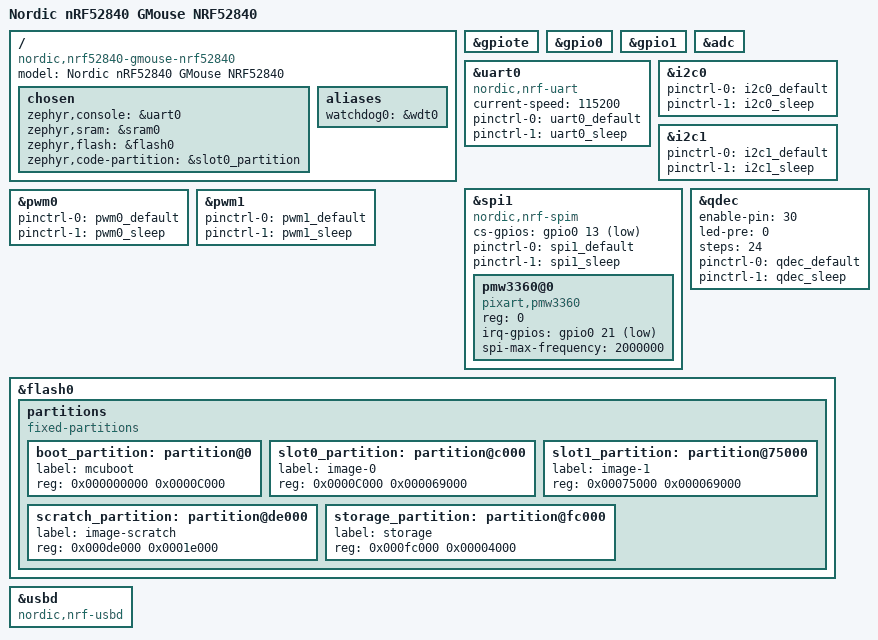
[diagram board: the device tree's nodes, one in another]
/*
 * Copyright (c) 2018-2022 Nordic Semiconductor ASA
 *
 * SPDX-License-Identifier: LicenseRef-Nordic-5-Clause
 */

/dts-v1/;
#include <nordic/nrf52840_qiaa.dtsi>
#include "nrf52840gmouse_nrf52840-pinctrl.dtsi"

/ {
	model = "Nordic nRF52840 GMouse NRF52840";
	compatible = "nordic,nrf52840-gmouse-nrf52840";

	chosen {
		zephyr,console = &uart0;
		zephyr,sram = &sram0;
		zephyr,flash = &flash0;
		zephyr,code-partition = &slot0_partition;
	};

	/* These aliases are provided for compatibility with samples */
	aliases {
		watchdog0 = &wdt0;
	};
};

&gpiote {
	status = "okay";
};

&gpio0 {
	status = "okay";
};

&gpio1 {
	status = "okay";
};

&adc {
	status = "okay";
};

&uart0 {
	status = "okay";
	compatible = "nordic,nrf-uart";
	current-speed = <115200>;
	pinctrl-0 = <&uart0_default>;
	pinctrl-1 = <&uart0_sleep>;
	pinctrl-names = "default", "sleep";
};

&i2c0 {
	status = "okay";
	pinctrl-0 = <&i2c0_default>;
	pinctrl-1 = <&i2c0_sleep>;
	pinctrl-names = "default", "sleep";
};

&i2c1 {
	status = "okay";
	pinctrl-0 = <&i2c1_default>;
	pinctrl-1 = <&i2c1_sleep>;
	pinctrl-names = "default", "sleep";
};

&spi1 {
	compatible = "nordic,nrf-spim";
	status = "okay";
	cs-gpios = <&gpio0 13 GPIO_ACTIVE_LOW>;

	pinctrl-0 = <&spi1_default>;
	pinctrl-1 = <&spi1_sleep>;
	pinctrl-names = "default", "sleep";
	pmw3360@0 {
		compatible = "pixart,pmw3360";
		reg = <0>;
		irq-gpios = <&gpio0 21 (GPIO_ACTIVE_LOW | GPIO_PULL_UP)>;
		spi-max-frequency = <2000000>;
	};
};

&qdec {
	status = "okay";
	enable-pin = <30>;
	led-pre = <0>;
	steps = <24>;
	pinctrl-0 = <&qdec_default>;
	pinctrl-1 = <&qdec_sleep>;
	pinctrl-names = "default", "sleep";
};

&pwm0 {
	status = "okay";
	pinctrl-0 = <&pwm0_default>;
	pinctrl-1 = <&pwm0_sleep>;
	pinctrl-names = "default", "sleep";
};

&pwm1 {
	status = "okay";
	pinctrl-0 = <&pwm1_default>;
	pinctrl-1 = <&pwm1_sleep>;
	pinctrl-names = "default", "sleep";
};

&flash0 {
	/*
	 * For more information, see:
	 * http://docs.zephyrproject.org/devices/dts/flash_partitions.html
	 */
	partitions {
		compatible = "fixed-partitions";
		#address-cells = <1>;
		#size-cells = <1>;

		boot_partition: partition@0 {
			label = "mcuboot";
			reg = <0x000000000 0x0000C000>;
		};
		slot0_partition: partition@c000 {
			label = "image-0";
			reg = <0x0000C000 0x000069000>;
		};
		slot1_partition: partition@75000 {
			label = "image-1";
			reg = <0x00075000 0x000069000>;
		};
		scratch_partition: partition@de000 {
			label = "image-scratch";
			reg = <0x000de000 0x0001e000>;
		};

		storage_partition: partition@fc000 {
			label = "storage";
			reg = <0x000fc000 0x00004000>;
		};
	};
};

zephyr_udc0: &usbd {
	compatible = "nordic,nrf-usbd";
	status = "okay";
};
